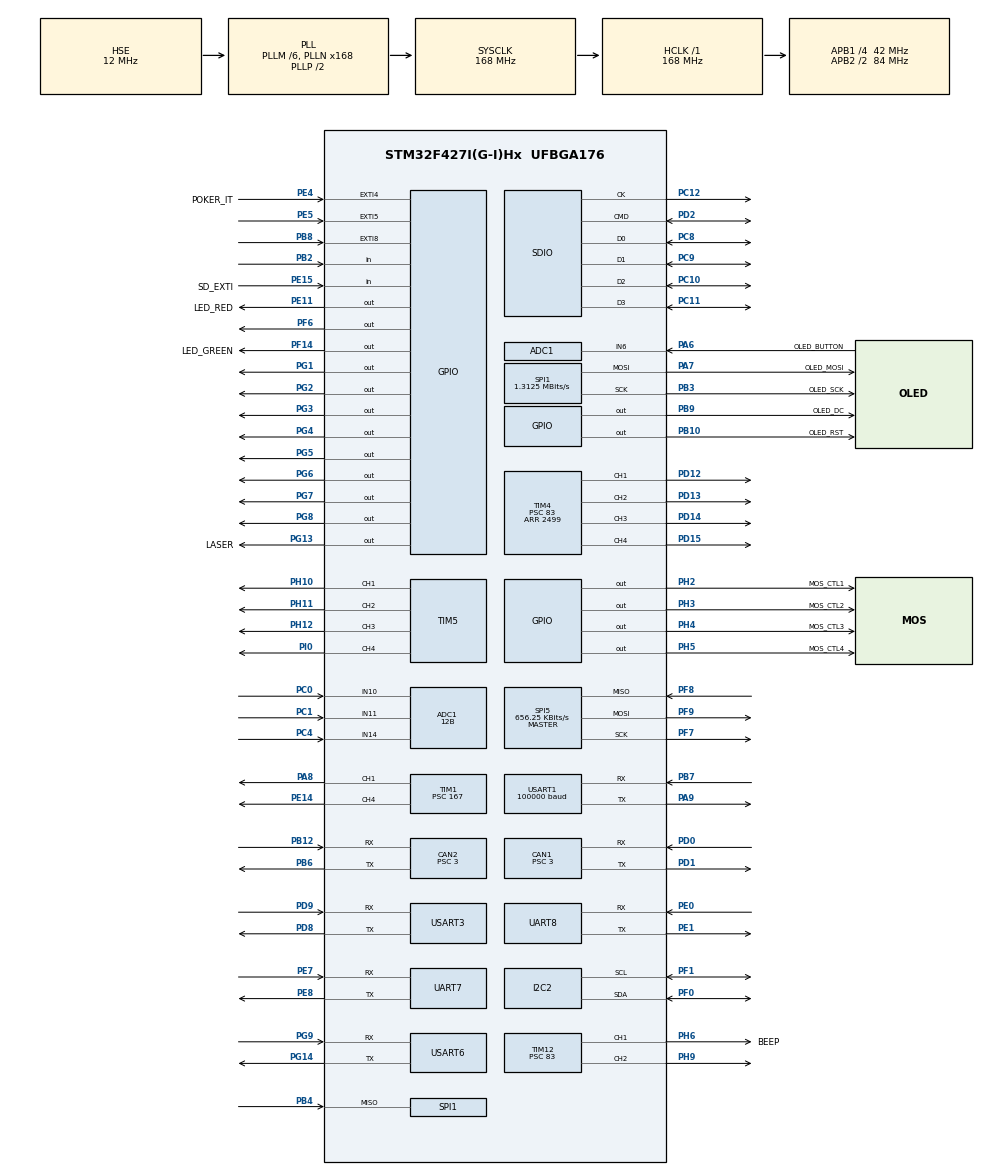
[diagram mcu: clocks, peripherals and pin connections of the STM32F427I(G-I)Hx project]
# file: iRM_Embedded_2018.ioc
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ADC1.Channel-5\#ChannelRegularConversion=ADC_CHANNEL_14
ADC1.Channel-6\#ChannelRegularConversion=ADC_CHANNEL_10
ADC1.Channel-7\#ChannelRegularConversion=ADC_CHANNEL_11
ADC1.Channel-8\#ChannelRegularConversion=ADC_CHANNEL_6
ADC1.ClockPrescaler=ADC_CLOCK_SYNC_PCLK_DIV4
ADC1.ContinuousConvMode=ENABLE
ADC1.DMAContinuousRequests=ENABLE
ADC1.DataAlign=ADC_DATAALIGN_RIGHT
ADC1.DiscontinuousConvMode=DISABLE
ADC1.EOCSelection=ADC_EOC_SEQ_CONV
ADC1.EnableAnalogWatchDog=false
ADC1.ExternalTrigConv=ADC_SOFTWARE_START
ADC1.ExternalTrigConvEdge=ADC_EXTERNALTRIGCONVEDGE_NONE
ADC1.InjNumberOfConversion=0
ADC1.NbrOfConversion=4
ADC1.NbrOfConversionFlag=1
ADC1.Rank-5\#ChannelRegularConversion=1
ADC1.Rank-6\#ChannelRegularConversion=2
ADC1.Rank-7\#ChannelRegularConversion=3
ADC1.Rank-8\#ChannelRegularConversion=4
ADC1.Resolution=ADC_RESOLUTION_12B
ADC1.SamplingTime-5\#ChannelRegularConversion=ADC_SAMPLETIME_144CYCLES
ADC1.SamplingTime-6\#ChannelRegularConversion=ADC_SAMPLETIME_144CYCLES
ADC1.SamplingTime-7\#ChannelRegularConversion=ADC_SAMPLETIME_144CYCLES
ADC1.SamplingTime-8\#ChannelRegularConversion=ADC_SAMPLETIME_144CYCLES
ADC1.ScanConvMode=ENABLE
ADC1.master=1
CAN1.ABOM=ENABLE
CAN1.BS1=CAN_BS1_9TQ
CAN1.BS2=CAN_BS2_4TQ
CAN1.CalculateTimeQuantum=71.42857142857143
CAN1.NART=ENABLE
CAN1.Prescaler=3
CAN2.ABOM=ENABLE
CAN2.BS1=CAN_BS1_9TQ
CAN2.BS2=CAN_BS2_4TQ
CAN2.CalculateTimeQuantum=71.42857142857143
CAN2.NART=ENABLE
CAN2.Prescaler=3
Dma.ADC1.4.Direction=DMA_PERIPH_TO_MEMORY
Dma.ADC1.4.FIFOMode=DMA_FIFOMODE_DISABLE
Dma.ADC1.4.Instance=DMA2_Stream0
Dma.ADC1.4.MemDataAlignment=DMA_MDATAALIGN_HALFWORD
Dma.ADC1.4.MemInc=DMA_MINC_ENABLE
Dma.ADC1.4.Mode=DMA_CIRCULAR
Dma.ADC1.4.PeriphDataAlignment=DMA_PDATAALIGN_HALFWORD
Dma.ADC1.4.PeriphInc=DMA_PINC_DISABLE
Dma.ADC1.4.Priority=DMA_PRIORITY_LOW
Dma.Request0=SDIO_TX
Dma.Request1=SDIO_RX
Dma.Request10=USART6_TX
Dma.Request2=UART8_RX
Dma.Request3=UART8_TX
Dma.Request4=ADC1
Dma.Request5=UART7_RX
Dma.Request6=USART1_RX
Dma.Request7=USART3_RX
Dma.Request8=USART3_TX
Dma.Request9=USART6_RX
Dma.SDIO_RX.1.Direction=DMA_PERIPH_TO_MEMORY
Dma.SDIO_RX.1.FIFOMode=DMA_FIFOMODE_ENABLE
Dma.SDIO_RX.1.FIFOThreshold=DMA_FIFO_THRESHOLD_FULL
Dma.SDIO_RX.1.Instance=DMA2_Stream6
Dma.SDIO_RX.1.MemBurst=DMA_MBURST_INC4
Dma.SDIO_RX.1.MemDataAlignment=DMA_MDATAALIGN_WORD
Dma.SDIO_RX.1.MemInc=DMA_MINC_ENABLE
Dma.SDIO_RX.1.Mode=DMA_PFCTRL
Dma.SDIO_RX.1.PeriphBurst=DMA_PBURST_INC4
Dma.SDIO_RX.1.PeriphDataAlignment=DMA_PDATAALIGN_WORD
Dma.SDIO_RX.1.PeriphInc=DMA_PINC_DISABLE
Dma.SDIO_RX.1.Priority=DMA_PRIORITY_LOW
Dma.SDIO_TX.0.Direction=DMA_MEMORY_TO_PERIPH
Dma.SDIO_TX.0.FIFOMode=DMA_FIFOMODE_ENABLE
Dma.SDIO_TX.0.FIFOThreshold=DMA_FIFO_THRESHOLD_FULL
Dma.SDIO_TX.0.Instance=DMA2_Stream3
Dma.SDIO_TX.0.MemBurst=DMA_MBURST_INC4
Dma.SDIO_TX.0.MemDataAlignment=DMA_MDATAALIGN_WORD
Dma.SDIO_TX.0.MemInc=DMA_MINC_ENABLE
Dma.SDIO_TX.0.Mode=DMA_PFCTRL
Dma.SDIO_TX.0.PeriphBurst=DMA_PBURST_INC4
Dma.SDIO_TX.0.PeriphDataAlignment=DMA_PDATAALIGN_WORD
Dma.SDIO_TX.0.PeriphInc=DMA_PINC_DISABLE
Dma.SDIO_TX.0.Priority=DMA_PRIORITY_LOW
Dma.UART7_RX.5.Direction=DMA_PERIPH_TO_MEMORY
Dma.UART7_RX.5.FIFOMode=DMA_FIFOMODE_DISABLE
Dma.UART7_RX.5.Instance=DMA1_Stream3
Dma.UART7_RX.5.MemDataAlignment=DMA_MDATAALIGN_BYTE
Dma.UART7_RX.5.MemInc=DMA_MINC_ENABLE
Dma.UART7_RX.5.Mode=DMA_NORMAL
Dma.UART7_RX.5.PeriphDataAlignment=DMA_PDATAALIGN_BYTE
Dma.UART7_RX.5.PeriphInc=DMA_PINC_DISABLE
Dma.UART7_RX.5.Priority=DMA_PRIORITY_LOW
Dma.UART8_RX.2.Direction=DMA_PERIPH_TO_MEMORY
Dma.UART8_RX.2.FIFOMode=DMA_FIFOMODE_DISABLE
Dma.UART8_RX.2.Instance=DMA1_Stream6
Dma.UART8_RX.2.MemDataAlignment=DMA_MDATAALIGN_BYTE
Dma.UART8_RX.2.MemInc=DMA_MINC_ENABLE
Dma.UART8_RX.2.Mode=DMA_NORMAL
Dma.UART8_RX.2.PeriphDataAlignment=DMA_PDATAALIGN_BYTE
Dma.UART8_RX.2.PeriphInc=DMA_PINC_DISABLE
Dma.UART8_RX.2.Priority=DMA_PRIORITY_LOW
Dma.UART8_TX.3.Direction=DMA_MEMORY_TO_PERIPH
Dma.UART8_TX.3.FIFOMode=DMA_FIFOMODE_DISABLE
Dma.UART8_TX.3.Instance=DMA1_Stream0
Dma.UART8_TX.3.MemDataAlignment=DMA_MDATAALIGN_BYTE
Dma.UART8_TX.3.MemInc=DMA_MINC_ENABLE
Dma.UART8_TX.3.Mode=DMA_NORMAL
Dma.UART8_TX.3.PeriphDataAlignment=DMA_PDATAALIGN_BYTE
Dma.UART8_TX.3.PeriphInc=DMA_PINC_DISABLE
Dma.UART8_TX.3.Priority=DMA_PRIORITY_LOW
Dma.USART1_RX.6.Direction=DMA_PERIPH_TO_MEMORY
Dma.USART1_RX.6.FIFOMode=DMA_FIFOMODE_DISABLE
Dma.USART1_RX.6.Instance=DMA2_Stream2
Dma.USART1_RX.6.MemDataAlignment=DMA_MDATAALIGN_BYTE
Dma.USART1_RX.6.MemInc=DMA_MINC_ENABLE
Dma.USART1_RX.6.Mode=DMA_CIRCULAR
Dma.USART1_RX.6.PeriphDataAlignment=DMA_PDATAALIGN_BYTE
Dma.USART1_RX.6.PeriphInc=DMA_PINC_DISABLE
Dma.USART1_RX.6.Priority=DMA_PRIORITY_LOW
Dma.USART3_RX.7.Direction=DMA_PERIPH_TO_MEMORY
Dma.USART3_RX.7.FIFOMode=DMA_FIFOMODE_DISABLE
Dma.USART3_RX.7.Instance=DMA1_Stream1
Dma.USART3_RX.7.MemDataAlignment=DMA_MDATAALIGN_BYTE
Dma.USART3_RX.7.MemInc=DMA_MINC_ENABLE
Dma.USART3_RX.7.Mode=DMA_NORMAL
Dma.USART3_RX.7.PeriphDataAlignment=DMA_PDATAALIGN_BYTE
Dma.USART3_RX.7.PeriphInc=DMA_PINC_DISABLE
Dma.USART3_RX.7.Priority=DMA_PRIORITY_LOW
Dma.USART3_TX.8.Direction=DMA_MEMORY_TO_PERIPH
Dma.USART3_TX.8.FIFOMode=DMA_FIFOMODE_DISABLE
Dma.USART3_TX.8.Instance=DMA1_Stream4
Dma.USART3_TX.8.MemDataAlignment=DMA_MDATAALIGN_BYTE
Dma.USART3_TX.8.MemInc=DMA_MINC_ENABLE
Dma.USART3_TX.8.Mode=DMA_NORMAL
Dma.USART3_TX.8.PeriphDataAlignment=DMA_PDATAALIGN_BYTE
Dma.USART3_TX.8.PeriphInc=DMA_PINC_DISABLE
Dma.USART3_TX.8.Priority=DMA_PRIORITY_LOW
Dma.USART6_RX.9.Direction=DMA_PERIPH_TO_MEMORY
Dma.USART6_RX.9.FIFOMode=DMA_FIFOMODE_DISABLE
Dma.USART6_RX.9.Instance=DMA2_Stream1
Dma.USART6_RX.9.MemDataAlignment=DMA_MDATAALIGN_BYTE
Dma.USART6_RX.9.MemInc=DMA_MINC_ENABLE
Dma.USART6_RX.9.Mode=DMA_NORMAL
Dma.USART6_RX.9.PeriphDataAlignment=DMA_PDATAALIGN_BYTE
Dma.USART6_RX.9.PeriphInc=DMA_PINC_DISABLE
Dma.USART6_RX.9.Priority=DMA_PRIORITY_LOW
Dma.USART6_TX.10.Direction=DMA_MEMORY_TO_PERIPH
Dma.USART6_TX.10.FIFOMode=DMA_FIFOMODE_DISABLE
Dma.USART6_TX.10.Instance=DMA2_Stream7
Dma.USART6_TX.10.MemDataAlignment=DMA_MDATAALIGN_BYTE
Dma.USART6_TX.10.MemInc=DMA_MINC_ENABLE
Dma.USART6_TX.10.Mode=DMA_NORMAL
Dma.USART6_TX.10.PeriphDataAlignment=DMA_PDATAALIGN_BYTE
Dma.USART6_TX.10.PeriphInc=DMA_PINC_DISABLE
Dma.USART6_TX.10.Priority=DMA_PRIORITY_LOW
FATFS.USE_DMA_CODE_SD=1
FATFS._USE_LFN=2
FREERTOS.INCLUDE_uxTaskGetStackHighWaterMark=1
FREERTOS.INCLUDE_vTaskDelayUntil=1
FREERTOS.Tasks01=defaultTask,-3,256,StartDefaultTask,Default,NULL,Dynamic,NULL,NULL
FREERTOS.configCHECK_FOR_STACK_OVERFLOW=0
FREERTOS.configTOTAL_HEAP_SIZE=65536
Mcu.Family=STM32F4
Mcu.Name=STM32F427I(G-I)Hx
Mcu.Package=UFBGA176
NVIC.ADC_IRQn=true\:5\:0\:false\:false\:true\:true\:true
NVIC.CAN1_RX0_IRQn=true\:5\:0\:false\:false\:true\:true\:true
NVIC.CAN1_TX_IRQn=true\:5\:0\:false\:false\:true\:true\:true
NVIC.CAN2_RX0_IRQn=true\:5\:0\:false\:false\:true\:true\:true
NVIC.CAN2_TX_IRQn=true\:5\:0\:false\:false\:true\:true\:true
NVIC.DMA1_Stream0_IRQn=true\:5\:0\:false\:false\:true\:true\:false
NVIC.DMA1_Stream1_IRQn=true\:5\:0\:false\:false\:true\:true\:false
NVIC.DMA1_Stream3_IRQn=true\:5\:0\:false\:false\:true\:true\:false
NVIC.DMA1_Stream4_IRQn=true\:5\:0\:false\:false\:true\:true\:false
NVIC.DMA1_Stream6_IRQn=true\:5\:0\:false\:false\:true\:true\:false
NVIC.DMA2_Stream0_IRQn=true\:5\:0\:false\:false\:true\:true\:false
NVIC.DMA2_Stream1_IRQn=true\:5\:0\:false\:false\:true\:true\:false
NVIC.DMA2_Stream2_IRQn=true\:5\:0\:false\:false\:true\:true\:false
NVIC.DMA2_Stream3_IRQn=true\:5\:0\:false\:false\:true\:true\:false
NVIC.DMA2_Stream6_IRQn=true\:5\:0\:false\:false\:true\:true\:false
NVIC.DMA2_Stream7_IRQn=true\:5\:0\:false\:false\:true\:true\:false
NVIC.EXTI4_IRQn=true\:5\:0\:false\:false\:true\:true\:true
NVIC.EXTI9_5_IRQn=true\:5\:0\:false\:false\:true\:true\:true
NVIC.PriorityGroup=NVIC_PRIORITYGROUP_4
NVIC.SDIO_IRQn=true\:5\:0\:false\:false\:true\:true\:true
NVIC.TIM3_IRQn=true\:0\:0\:false\:false\:true\:false\:false
NVIC.TimeBase=TIM3_IRQn
NVIC.TimeBaseIP=TIM3
NVIC.UART7_IRQn=true\:5\:0\:false\:false\:true\:true\:true
NVIC.UART8_IRQn=true\:5\:0\:false\:false\:true\:true\:true
NVIC.USART1_IRQn=true\:5\:0\:false\:false\:true\:true\:true
NVIC.USART3_IRQn=true\:5\:0\:false\:false\:true\:true\:true
NVIC.USART6_IRQn=true\:5\:0\:false\:false\:true\:true\:true
PA13.Mode=Serial_Wire
PA13.Signal=SYS_JTMS-SWDIO
PA14.Mode=Serial_Wire
PA14.Signal=SYS_JTCK-SWCLK
PA6.GPIO_Label=OLED_BUTTON
PA6.Signal=ADCx_IN6
PA7.GPIO_Label=OLED_MOSI
PA7.Mode=Full_Duplex_Master
PA7.Signal=SPI1_MOSI
PA8.Signal=S_TIM1_CH1
PA9.Mode=Asynchronous
PA9.Signal=USART1_TX
PB10.GPIO_Label=OLED_RST
PB10.Signal=GPIO_Output
PB12.Mode=Slave
PB12.Signal=CAN2_RX
PB2/BOOT1.Signal=GPIO_Input
PB3.GPIO_Label=OLED_SCK
PB3.Mode=Full_Duplex_Master
PB3.Signal=SPI1_SCK
PB4.Mode=Full_Duplex_Master
PB4.Signal=SPI1_MISO
PB6.Mode=Slave
PB6.Signal=CAN2_TX
PB7.Mode=Asynchronous
PB7.Signal=USART1_RX
PB8.GPIO_ModeDefaultEXTI=GPIO_MODE_IT_RISING
PB8.Signal=GPXTI8
PB9.GPIO_Label=OLED_DC
PB9.Signal=GPIO_Output
PC0.Signal=ADCx_IN10
PC1.Signal=ADCx_IN11
PC10.Mode=SD_4_bits_Wide_bus
PC10.Signal=SDIO_D2
PC11.Mode=SD_4_bits_Wide_bus
PC11.Signal=SDIO_D3
PC12.Mode=SD_4_bits_Wide_bus
PC12.Signal=SDIO_CK
PC4.Signal=ADCx_IN14
PC8.Mode=SD_4_bits_Wide_bus
PC8.Signal=SDIO_D0
PC9.Mode=SD_4_bits_Wide_bus
PC9.Signal=SDIO_D1
PD0.Mode=Master
PD0.Signal=CAN1_RX
PD1.Mode=Master
PD1.Signal=CAN1_TX
PD12.Signal=S_TIM4_CH1
PD13.Signal=S_TIM4_CH2
PD14.Signal=S_TIM4_CH3
PD15.Signal=S_TIM4_CH4
PD2.Mode=SD_4_bits_Wide_bus
PD2.Signal=SDIO_CMD
PD8.Mode=Asynchronous
PD8.Signal=USART3_TX
PD9.Mode=Asynchronous
PD9.Signal=USART3_RX
PE0.Mode=Asynchronous
PE0.Signal=UART8_RX
PE1.Mode=Asynchronous
PE1.Signal=UART8_TX
PE11.GPIO_Label=LED_RED
PE11.Signal=GPIO_Output
PE14.Signal=S_TIM1_CH4
PE15.GPIO_Label=SD_EXTI
PE15.Signal=GPIO_Input
PE4.GPIO_Label=POKER_IT
PE4.GPIO_ModeDefaultEXTI=GPIO_MODE_IT_RISING
PE4.Signal=GPXTI4
PE5.Signal=GPXTI5
PE7.Mode=Asynchronous
PE7.Signal=UART7_RX
PE8.Mode=Asynchronous
PE8.Signal=UART7_TX
PF0.Mode=I2C
PF0.Signal=I2C2_SDA
PF1.Mode=I2C
PF1.Signal=I2C2_SCL
PF14.GPIO_Label=LED_GREEN
PF14.Signal=GPIO_Output
PF6.Signal=GPIO_Output
PF7.Mode=Full_Duplex_Master
PF7.Signal=SPI5_SCK
PF8.Mode=Full_Duplex_Master
PF8.Signal=SPI5_MISO
PF9.Mode=Full_Duplex_Master
PF9.Signal=SPI5_MOSI
PG1.Signal=GPIO_Output
PG13.GPIO_Label=LASER
PG13.Signal=GPIO_Output
PG14.Mode=Asynchronous
PG14.Signal=USART6_TX
PG2.Signal=GPIO_Output
PG3.Signal=GPIO_Output
PG4.Signal=GPIO_Output
PG5.Signal=GPIO_Output
PG6.Signal=GPIO_Output
PG7.Signal=GPIO_Output
PG8.Signal=GPIO_Output
PG9.Mode=Asynchronous
PG9.Signal=USART6_RX
PH0/OSC_IN.Mode=HSE-External-Oscillator
PH0/OSC_IN.Signal=RCC_OSC_IN
PH1/OSC_OUT.Mode=HSE-External-Oscillator
PH1/OSC_OUT.Signal=RCC_OSC_OUT
PH10.Signal=S_TIM5_CH1
PH11.Signal=S_TIM5_CH2
PH12.Signal=S_TIM5_CH3
PH2.GPIO_Label=MOS_CTL1
PH2.PinState=GPIO_PIN_SET
PH2.Signal=GPIO_Output
PH3.GPIO_Label=MOS_CTL2
PH3.PinState=GPIO_PIN_SET
PH3.Signal=GPIO_Output
PH4.GPIO_Label=MOS_CTL3
PH4.PinState=GPIO_PIN_SET
PH4.Signal=GPIO_Output
PH5.GPIO_Label=MOS_CTL4
PH5.PinState=GPIO_PIN_SET
PH5.Signal=GPIO_Output
PH6.GPIO_Label=BEEP
PH6.Signal=S_TIM12_CH1
PH9.Signal=S_TIM12_CH2
PI0.Signal=S_TIM5_CH4
ProjectManager.HeapSize=0x800
ProjectManager.StackSize=0x1000
ProjectManager.TargetToolchain=SW4STM32
RCC.48MHZClocksFreq_Value=48000000
RCC.AHBFreq_Value=168000000
RCC.APB1CLKDivider=RCC_HCLK_DIV4
RCC.APB1Freq_Value=42000000
RCC.APB1TimFreq_Value=84000000
RCC.APB2CLKDivider=RCC_HCLK_DIV2
RCC.APB2Freq_Value=84000000
RCC.APB2TimFreq_Value=168000000
RCC.CortexFreq_Value=168000000
RCC.HCLKFreq_Value=168000000
RCC.HSE_VALUE=12000000
RCC.HSI_VALUE=16000000
RCC.LSE_VALUE=32768
RCC.PLLM=6
RCC.PLLN=168
RCC.PLLQ=7
RCC.PLLSourceVirtual=RCC_PLLSOURCE_HSE
RCC.SYSCLKFreq_VALUE=168000000
RCC.SYSCLKSource=RCC_SYSCLKSOURCE_PLLCLK
RCC.VCOOutputFreq_Value=336000000
SH.ADCx_IN10.0=ADC1_IN10,IN10
SH.ADCx_IN11.0=ADC1_IN11,IN11
SH.ADCx_IN14.0=ADC1_IN14,IN14
SH.ADCx_IN6.0=ADC1_IN6,IN6
SH.S_TIM12_CH1.0=TIM12_CH1,PWM Generation1 CH1
SH.S_TIM12_CH2.0=TIM12_CH2,PWM Generation2 CH2
SH.S_TIM1_CH1.0=TIM1_CH1,PWM Generation1 CH1
SH.S_TIM1_CH4.0=TIM1_CH4,PWM Generation4 CH4
SH.S_TIM4_CH1.0=TIM4_CH1,PWM Generation1 CH1
SH.S_TIM4_CH2.0=TIM4_CH2,PWM Generation2 CH2
SH.S_TIM4_CH3.0=TIM4_CH3,PWM Generation3 CH3
SH.S_TIM4_CH4.0=TIM4_CH4,PWM Generation4 CH4
SH.S_TIM5_CH1.0=TIM5_CH1,PWM Generation1 CH1
SH.S_TIM5_CH2.0=TIM5_CH2,PWM Generation2 CH2
SH.S_TIM5_CH3.0=TIM5_CH3,PWM Generation3 CH3
SH.S_TIM5_CH4.0=TIM5_CH4,PWM Generation4 CH4
SPI1.BaudRatePrescaler=SPI_BAUDRATEPRESCALER_64
SPI1.CalculateBaudRate=1.3125 MBits/s
SPI1.Direction=SPI_DIRECTION_2LINES
SPI1.Mode=SPI_MODE_MASTER
SPI1.VirtualType=VM_MASTER
SPI5.BaudRatePrescaler=SPI_BAUDRATEPRESCALER_128
SPI5.CalculateBaudRate=656.25 KBits/s
SPI5.Direction=SPI_DIRECTION_2LINES
SPI5.Mode=SPI_MODE_MASTER
SPI5.VirtualType=VM_MASTER
TIM1.Channel-PWM\ Generation1\ CH1=TIM_CHANNEL_1
TIM1.Channel-PWM\ Generation4\ CH4=TIM_CHANNEL_4
TIM1.Period=2499
TIM1.Prescaler=167
TIM1.Pulse-PWM\ Generation1\ CH1=1000
TIM1.Pulse-PWM\ Generation4\ CH4=1000
TIM12.Channel-PWM\ Generation1\ CH1=TIM_CHANNEL_1
TIM12.Channel-PWM\ Generation2\ CH2=TIM_CHANNEL_2
TIM12.Prescaler=83
TIM4.Channel-PWM\ Generation1\ CH1=TIM_CHANNEL_1
TIM4.Channel-PWM\ Generation2\ CH2=TIM_CHANNEL_2
TIM4.Channel-PWM\ Generation3\ CH3=TIM_CHANNEL_3
TIM4.Channel-PWM\ Generation4\ CH4=TIM_CHANNEL_4
TIM4.Period=2499
TIM4.Prescaler=83
TIM4.Pulse-PWM\ Generation1\ CH1=1000
TIM4.Pulse-PWM\ Generation2\ CH2=1000
TIM5.Channel-PWM\ Generation1\ CH1=TIM_CHANNEL_1
TIM5.Channel-PWM\ Generation2\ CH2=TIM_CHANNEL_2
TIM5.Channel-PWM\ Generation3\ CH3=TIM_CHANNEL_3
TIM5.Channel-PWM\ Generation4\ CH4=TIM_CHANNEL_4
UART7.VirtualMode=Asynchronous
UART8.VirtualMode=Asynchronous
USART1.BaudRate=100000
USART1.VirtualMode=VM_ASYNC
USART3.VirtualMode=VM_ASYNC
USART6.VirtualMode=VM_ASYNC
VP_FATFS_VS_SDIO.Mode=SDIO
VP_FREERTOS_VS_ENABLE.Mode=Enabled
VP_SYS_VS_tim3.Mode=TIM3
VP_TIM12_VS_ClockSourceINT.Mode=Internal
VP_TIM1_VS_ClockSourceINT.Mode=Internal
VP_TIM4_VS_ClockSourceINT.Mode=Internal
VP_TIM5_VS_ClockSourceINT.Mode=Internal
board=iRM_2018_Type_A

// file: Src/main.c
/**
  ******************************************************************************
  * @file           : main.c
  * @brief          : Main program body
  ******************************************************************************
  * This notice applies to any and all portions of this file
  * that are not between comment pairs USER CODE BEGIN and
  * USER CODE END. Other portions of this file, whether
  * inserted by the user or by software development tools
  * are owned by their respective copyright owners.
  *
  * Copyright (c) 2018 STMicroelectronics International N.V.
  * All rights reserved.
  *
  * Redistribution and use in source and binary forms, with or without
  * modification, are permitted, provided that the following conditions are met:
  *
  * 1. Redistribution of source code must retain the above copyright notice,
  *    this list of conditions and the following disclaimer.
  * 2. Redistributions in binary form must reproduce the above copyright notice,
  *    this list of conditions and the following disclaimer in the documentation
  *    and/or other materials provided with the distribution.
  * 3. Neither the name of STMicroelectronics nor the names of other
  *    contributors to this software may be used to endorse or promote products
  *    derived from this software without specific written permission.
  * 4. This software, including modifications and/or derivative works of this
  *    software, must execute solely and exclusively on microcontroller or
  *    microprocessor devices manufactured by or for STMicroelectronics.
  * 5. Redistribution and use of this software other than as permitted under
  *    this license is void and will automatically terminate your rights under
  *    this license.
  *
  * THIS SOFTWARE IS PROVIDED BY STMICROELECTRONICS AND CONTRIBUTORS "AS IS"
  * AND ANY EXPRESS, IMPLIED OR STATUTORY WARRANTIES, INCLUDING, BUT NOT
  * LIMITED TO, THE IMPLIED WARRANTIES OF MERCHANTABILITY, FITNESS FOR A
  * PARTICULAR PURPOSE AND NON-INFRINGEMENT OF THIRD PARTY INTELLECTUAL PROPERTY
  * RIGHTS ARE DISCLAIMED TO THE FULLEST EXTENT PERMITTED BY LAW. IN NO EVENT
  * SHALL STMICROELECTRONICS OR CONTRIBUTORS BE LIABLE FOR ANY DIRECT, INDIRECT,
  * INCIDENTAL, SPECIAL, EXEMPLARY, OR CONSEQUENTIAL DAMAGES (INCLUDING, BUT NOT
  * LIMITED TO, PROCUREMENT OF SUBSTITUTE GOODS OR SERVICES; LOSS OF USE, DATA,
  * OR PROFITS; OR BUSINESS INTERRUPTION) HOWEVER CAUSED AND ON ANY THEORY OF
  * LIABILITY, WHETHER IN CONTRACT, STRICT LIABILITY, OR TORT (INCLUDING
  * NEGLIGENCE OR OTHERWISE) ARISING IN ANY WAY OUT OF THE USE OF THIS SOFTWARE,
  * EVEN IF ADVISED OF THE POSSIBILITY OF SUCH DAMAGE.
  *
  ******************************************************************************
  */
#include "main.h"
#include "stm32f4xx_hal.h"
#include "cmsis_os.h"
#include "adc.h"
#include "can.h"
#include "dma.h"
#include "fatfs.h"
#include "i2c.h"
#include "sdio.h"
#include "spi.h"
#include "tim.h"
#include "usart.h"
#include "gpio.h"

/* USER CODE BEGIN Includes */
#include "rm_main.h"
/* USER CODE END Includes */

/* USER CODE BEGIN PV */
/* Private variables ---------------------------------------------------------*/

/* USER CODE END PV */

void SystemClock_Config(void);
void MX_FREERTOS_Init(void);

/* USER CODE BEGIN PFP */
/* Private function prototypes -----------------------------------------------*/

/* USER CODE END PFP */

int main(void)
{

  /* MCU Configuration----------------------------------------------------------*/

  /* Reset of all peripherals, Initializes the Flash interface and the Systick. */
  HAL_Init();

  /* Configure the system clock */
  SystemClock_Config();

  /* Initialize all configured peripherals */
  MX_GPIO_Init();
  MX_DMA_Init();
  MX_SDIO_SD_Init();
  MX_USART6_UART_Init();
  MX_TIM12_Init();
  MX_SPI1_Init();
  MX_ADC1_Init();
  MX_SPI5_Init();
  MX_CAN1_Init();
  MX_CAN2_Init();
  MX_USART3_UART_Init();
  MX_UART7_Init();
  MX_UART8_Init();
  MX_TIM4_Init();
  MX_TIM5_Init();
  MX_USART1_UART_Init();
  MX_TIM1_Init();
  MX_I2C2_Init();
  /* USER CODE BEGIN 2 */
  RM_Main_Init();
  /* USER CODE END 2 */

  /* Call init function for freertos objects (in freertos.c) */
  MX_FREERTOS_Init();

  /* Start scheduler */
  osKernelStart();

  /* We should never get here as control is now taken by the scheduler */

  /* Infinite loop */
  while (1)
  {

  }

}

void SystemClock_Config(void)
{

  RCC_OscInitTypeDef RCC_OscInitStruct;
  RCC_ClkInitTypeDef RCC_ClkInitStruct;

    /**Configure the main internal regulator output voltage
    */
  __HAL_RCC_PWR_CLK_ENABLE();

  __HAL_PWR_VOLTAGESCALING_CONFIG(PWR_REGULATOR_VOLTAGE_SCALE1);

    /**Initializes the CPU, AHB and APB busses clocks
    */
  RCC_OscInitStruct.OscillatorType = RCC_OSCILLATORTYPE_HSE;
  RCC_OscInitStruct.HSEState = RCC_HSE_ON;
  RCC_OscInitStruct.PLL.PLLState = RCC_PLL_ON;
  RCC_OscInitStruct.PLL.PLLSource = RCC_PLLSOURCE_HSE;
  RCC_OscInitStruct.PLL.PLLM = 6;
  RCC_OscInitStruct.PLL.PLLN = 168;
  RCC_OscInitStruct.PLL.PLLP = RCC_PLLP_DIV2;
  RCC_OscInitStruct.PLL.PLLQ = 7;
  if (HAL_RCC_OscConfig(&RCC_OscInitStruct) != HAL_OK)
  {
    _Error_Handler(__FILE__, __LINE__);
  }

    /**Initializes the CPU, AHB and APB busses clocks
    */
  RCC_ClkInitStruct.ClockType = RCC_CLOCKTYPE_HCLK|RCC_CLOCKTYPE_SYSCLK
                              |RCC_CLOCKTYPE_PCLK1|RCC_CLOCKTYPE_PCLK2;
  RCC_ClkInitStruct.SYSCLKSource = RCC_SYSCLKSOURCE_PLLCLK;
  RCC_ClkInitStruct.AHBCLKDivider = RCC_SYSCLK_DIV1;
  RCC_ClkInitStruct.APB1CLKDivider = RCC_HCLK_DIV4;
  RCC_ClkInitStruct.APB2CLKDivider = RCC_HCLK_DIV2;

  if (HAL_RCC_ClockConfig(&RCC_ClkInitStruct, FLASH_LATENCY_5) != HAL_OK)
  {
    _Error_Handler(__FILE__, __LINE__);
  }

    /**Configure the Systick interrupt time
    */
  HAL_SYSTICK_Config(HAL_RCC_GetHCLKFreq()/1000);

    /**Configure the Systick
    */
  HAL_SYSTICK_CLKSourceConfig(SYSTICK_CLKSOURCE_HCLK);

  /* SysTick_IRQn interrupt configuration */
  HAL_NVIC_SetPriority(SysTick_IRQn, 15, 0);
}

void HAL_TIM_PeriodElapsedCallback(TIM_HandleTypeDef *htim)
{
  if (htim->Instance == TIM3) {
    HAL_IncTick();
  }
}

void _Error_Handler(char *file, int line)
{
  while(1)
  {
  }
}

/************************ (C) COPYRIGHT STMicroelectronics *****END OF FILE****/

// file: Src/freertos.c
/**
  ******************************************************************************
  * File Name          : freertos.c
  * Description        : Code for freertos applications
  ******************************************************************************
  * This notice applies to any and all portions of this file
  * that are not between comment pairs USER CODE BEGIN and
  * USER CODE END. Other portions of this file, whether
  * inserted by the user or by software development tools
  * are owned by their respective copyright owners.
  *
  * Copyright (c) 2018 STMicroelectronics International N.V.
  * All rights reserved.
  *
  * Redistribution and use in source and binary forms, with or without
  * modification, are permitted, provided that the following conditions are met:
  *
  * 1. Redistribution of source code must retain the above copyright notice,
  *    this list of conditions and the following disclaimer.
  * 2. Redistributions in binary form must reproduce the above copyright notice,
  *    this list of conditions and the following disclaimer in the documentation
  *    and/or other materials provided with the distribution.
  * 3. Neither the name of STMicroelectronics nor the names of other
  *    contributors to this software may be used to endorse or promote products
  *    derived from this software without specific written permission.
  * 4. This software, including modifications and/or derivative works of this
  *    software, must execute solely and exclusively on microcontroller or
  *    microprocessor devices manufactured by or for STMicroelectronics.
  * 5. Redistribution and use of this software other than as permitted under
  *    this license is void and will automatically terminate your rights under
  *    this license.
  *
  * THIS SOFTWARE IS PROVIDED BY STMICROELECTRONICS AND CONTRIBUTORS "AS IS"
  * AND ANY EXPRESS, IMPLIED OR STATUTORY WARRANTIES, INCLUDING, BUT NOT
  * LIMITED TO, THE IMPLIED WARRANTIES OF MERCHANTABILITY, FITNESS FOR A
  * PARTICULAR PURPOSE AND NON-INFRINGEMENT OF THIRD PARTY INTELLECTUAL PROPERTY
  * RIGHTS ARE DISCLAIMED TO THE FULLEST EXTENT PERMITTED BY LAW. IN NO EVENT
  * SHALL STMICROELECTRONICS OR CONTRIBUTORS BE LIABLE FOR ANY DIRECT, INDIRECT,
  * INCIDENTAL, SPECIAL, EXEMPLARY, OR CONSEQUENTIAL DAMAGES (INCLUDING, BUT NOT
  * LIMITED TO, PROCUREMENT OF SUBSTITUTE GOODS OR SERVICES; LOSS OF USE, DATA,
  * OR PROFITS; OR BUSINESS INTERRUPTION) HOWEVER CAUSED AND ON ANY THEORY OF
  * LIABILITY, WHETHER IN CONTRACT, STRICT LIABILITY, OR TORT (INCLUDING
  * NEGLIGENCE OR OTHERWISE) ARISING IN ANY WAY OUT OF THE USE OF THIS SOFTWARE,
  * EVEN IF ADVISED OF THE POSSIBILITY OF SUCH DAMAGE.
  *
  ******************************************************************************
  */

#include "FreeRTOS.h"
#include "task.h"
#include "cmsis_os.h"

/* USER CODE BEGIN Includes */
#include "rm_rtos.h"
/* USER CODE END Includes */

osThreadId defaultTaskHandle;

void StartDefaultTask(void const * argument);

extern void MX_FATFS_Init(void);
void MX_FREERTOS_Init(void); /* (MISRA C 2004 rule 8.1) */

/* Hook prototypes */

/* Init FreeRTOS */

void MX_FREERTOS_Init(void) {
  /* USER CODE BEGIN Init */
  RM_RTOS_Init();
  /* USER CODE END Init */

  /* USER CODE BEGIN RTOS_MUTEX */
  /* add mutexes, ... */
  RM_RTOS_MUTEX_Init();
  /* USER CODE END RTOS_MUTEX */

  /* USER CODE BEGIN RTOS_SEMAPHORES */
  /* add semaphores, ... */
  RM_RTOS_SEMAPHORES_Init();
  /* USER CODE END RTOS_SEMAPHORES */

  /* USER CODE BEGIN RTOS_TIMERS */
  /* start timers, add new ones, ... */
  RM_RTOS_TIMERS_Init();
  /* USER CODE END RTOS_TIMERS */

  /* Create the thread(s) */
  /* definition and creation of defaultTask */
  osThreadDef(defaultTask, StartDefaultTask, osPriorityIdle, 0, 256);
  defaultTaskHandle = osThreadCreate(osThread(defaultTask), NULL);

  /* USER CODE BEGIN RTOS_THREADS */
  /* add threads, ... */
  RM_RTOS_THREADS_Init();
  /* USER CODE END RTOS_THREADS */

  /* USER CODE BEGIN RTOS_QUEUES */
  /* add queues, ... */
  RM_RTOS_QUEUES_Init();
  RM_RTOS_Ready();
  /* USER CODE END RTOS_QUEUES */
}

/* StartDefaultTask function */
void StartDefaultTask(void const * argument)
{
  /* init code for FATFS */
  MX_FATFS_Init();

  /* USER CODE BEGIN StartDefaultTask */
  RM_RTOS_Default_Task(argument);
  /* USER CODE END StartDefaultTask */
}

/************************ (C) COPYRIGHT STMicroelectronics *****END OF FILE****/
